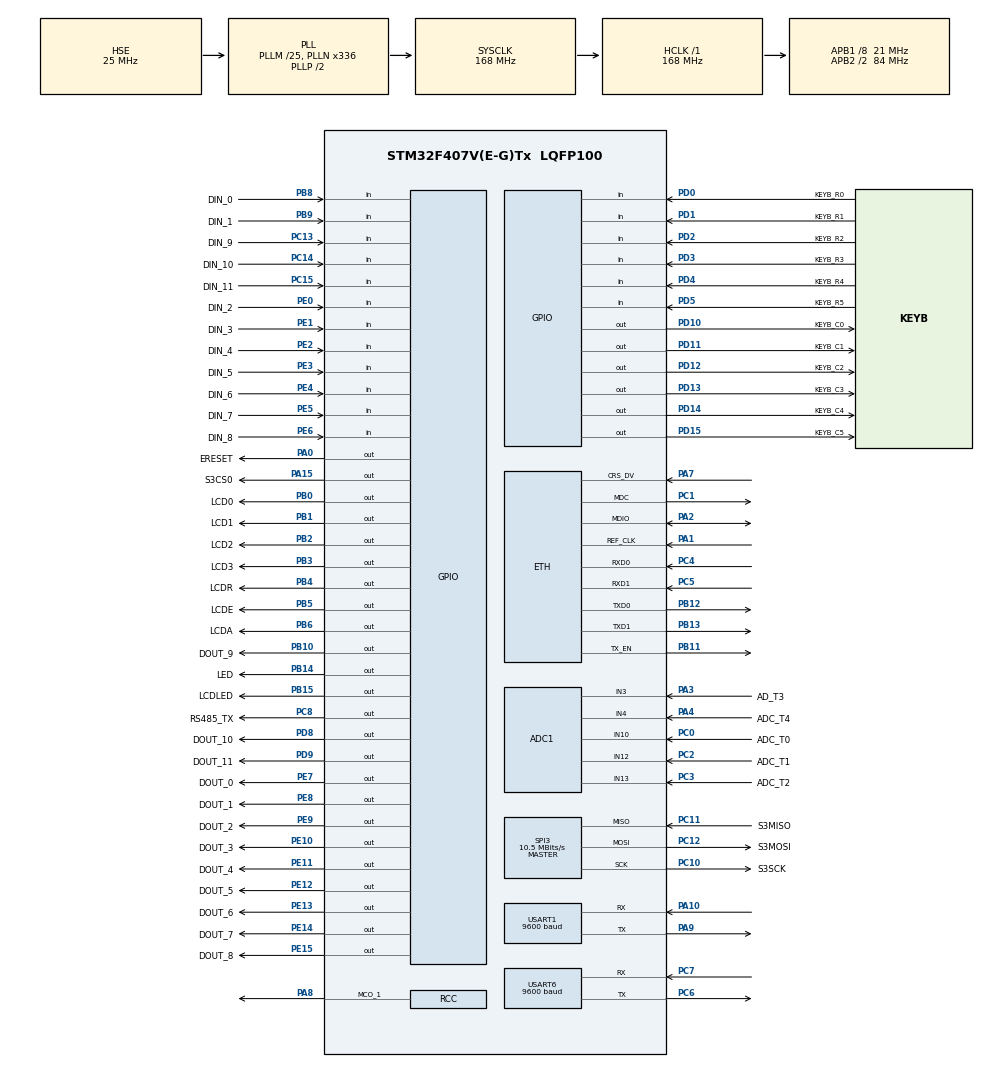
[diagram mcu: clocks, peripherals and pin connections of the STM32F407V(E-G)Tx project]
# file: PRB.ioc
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ADC1.Channel-0\#ChannelRegularConversion=ADC_CHANNEL_10
ADC1.Channel-1\#ChannelRegularConversion=ADC_CHANNEL_12
ADC1.Channel-2\#ChannelRegularConversion=ADC_CHANNEL_13
ADC1.Channel-3\#ChannelRegularConversion=ADC_CHANNEL_3
ADC1.Channel-4\#ChannelRegularConversion=ADC_CHANNEL_4
ADC1.Channel-5\#ChannelRegularConversion=ADC_CHANNEL_VREFINT
ADC1.ContinuousConvMode=DISABLE
ADC1.DMAContinuousRequests=ENABLE
ADC1.ExternalTrigConv=ADC_EXTERNALTRIGCONV_T3_TRGO
ADC1.InjNumberOfConversion=0
ADC1.NbrOfConversion=6
ADC1.NbrOfConversionFlag=1
ADC1.Rank-0\#ChannelRegularConversion=1
ADC1.Rank-1\#ChannelRegularConversion=2
ADC1.Rank-2\#ChannelRegularConversion=3
ADC1.Rank-3\#ChannelRegularConversion=4
ADC1.Rank-4\#ChannelRegularConversion=5
ADC1.Rank-5\#ChannelRegularConversion=6
ADC1.SamplingTime-0\#ChannelRegularConversion=ADC_SAMPLETIME_480CYCLES
ADC1.SamplingTime-1\#ChannelRegularConversion=ADC_SAMPLETIME_480CYCLES
ADC1.SamplingTime-2\#ChannelRegularConversion=ADC_SAMPLETIME_480CYCLES
ADC1.SamplingTime-3\#ChannelRegularConversion=ADC_SAMPLETIME_480CYCLES
ADC1.SamplingTime-4\#ChannelRegularConversion=ADC_SAMPLETIME_480CYCLES
ADC1.SamplingTime-5\#ChannelRegularConversion=ADC_SAMPLETIME_480CYCLES
ADC1.ScanConvMode=ENABLE
ADC1.master=1
Dma.ADC1.2.Direction=DMA_PERIPH_TO_MEMORY
Dma.ADC1.2.FIFOMode=DMA_FIFOMODE_DISABLE
Dma.ADC1.2.Instance=DMA2_Stream0
Dma.ADC1.2.MemDataAlignment=DMA_MDATAALIGN_HALFWORD
Dma.ADC1.2.MemInc=DMA_MINC_ENABLE
Dma.ADC1.2.Mode=DMA_CIRCULAR
Dma.ADC1.2.PeriphDataAlignment=DMA_PDATAALIGN_HALFWORD
Dma.ADC1.2.PeriphInc=DMA_PINC_DISABLE
Dma.ADC1.2.Priority=DMA_PRIORITY_LOW
Dma.Request0=USART1_RX
Dma.Request1=USART6_RX
Dma.Request2=ADC1
Dma.USART1_RX.0.Direction=DMA_PERIPH_TO_MEMORY
Dma.USART1_RX.0.FIFOMode=DMA_FIFOMODE_DISABLE
Dma.USART1_RX.0.Instance=DMA2_Stream2
Dma.USART1_RX.0.MemDataAlignment=DMA_MDATAALIGN_BYTE
Dma.USART1_RX.0.MemInc=DMA_MINC_ENABLE
Dma.USART1_RX.0.Mode=DMA_NORMAL
Dma.USART1_RX.0.PeriphDataAlignment=DMA_PDATAALIGN_BYTE
Dma.USART1_RX.0.PeriphInc=DMA_PINC_DISABLE
Dma.USART1_RX.0.Priority=DMA_PRIORITY_LOW
Dma.USART6_RX.1.Direction=DMA_PERIPH_TO_MEMORY
Dma.USART6_RX.1.FIFOMode=DMA_FIFOMODE_DISABLE
Dma.USART6_RX.1.Instance=DMA2_Stream1
Dma.USART6_RX.1.MemDataAlignment=DMA_MDATAALIGN_BYTE
Dma.USART6_RX.1.MemInc=DMA_MINC_ENABLE
Dma.USART6_RX.1.Mode=DMA_NORMAL
Dma.USART6_RX.1.PeriphDataAlignment=DMA_PDATAALIGN_BYTE
Dma.USART6_RX.1.PeriphInc=DMA_PINC_DISABLE
Dma.USART6_RX.1.Priority=DMA_PRIORITY_LOW
ETH.AutoNegotiation=ETH_AUTONEGOTIATION_ENABLE
ETH.DuplexMode=ETH_MODE_FULLDUPLEX
ETH.MACAddr=00\:80\:E1\:00\:13\:00
ETH.MediaInterface=ETH_MEDIA_INTERFACE_RMII
ETH.PhyAddress=0
FREERTOS.BinarySemaphores01=writeMemorySemaphore,Dynamic,NULL
FREERTOS.Tasks01=defaultTask,0,128,StartDefaultTask,Default,NULL,Dynamic,NULL,NULL
FREERTOS.configTOTAL_HEAP_SIZE=25360
FREERTOS.configUSE_NEWLIB_REENTRANT=1
LWIP.GATEWAY_ADDRESS=192.168.001.001
LWIP.IP_ADDRESS=192.168.001.177
LWIP.LWIP_DHCP=0
LWIP.NETMASK_ADDRESS=255.255.255.000
LWIP.Version=v2.1.2_Cube
Mcu.Family=STM32F4
Mcu.Name=STM32F407V(E-G)Tx
Mcu.Package=LQFP100
NVIC.DMA2_Stream0_IRQn=true\:5\:0\:false\:false\:true\:true\:false\:true
NVIC.DMA2_Stream1_IRQn=true\:5\:0\:false\:false\:true\:true\:false\:true
NVIC.DMA2_Stream2_IRQn=true\:5\:0\:false\:false\:true\:true\:false\:true
NVIC.ETH_IRQn=true\:5\:0\:false\:false\:true\:true\:false\:true
NVIC.PriorityGroup=NVIC_PRIORITYGROUP_4
NVIC.TIM1_UP_TIM10_IRQn=true\:15\:0\:false\:false\:true\:false\:false\:true
NVIC.TIM4_IRQn=true\:5\:0\:false\:false\:true\:true\:true\:true
NVIC.TimeBase=TIM1_UP_TIM10_IRQn
NVIC.TimeBaseIP=TIM1
NVIC.USART1_IRQn=true\:5\:0\:false\:false\:true\:true\:true\:true
NVIC.USART6_IRQn=true\:5\:0\:false\:false\:true\:true\:true\:true
PA0-WKUP.GPIO_Label=ERESET
PA0-WKUP.Signal=GPIO_Output
PA1.Mode=RMII
PA1.Signal=ETH_REF_CLK
PA10.GPIO_PuPd=GPIO_NOPULL
PA10.Mode=Asynchronous
PA10.Signal=USART1_RX
PA13.Mode=Serial_Wire
PA13.Signal=SYS_JTMS-SWDIO
PA14.Mode=Serial_Wire
PA14.Signal=SYS_JTCK-SWCLK
PA15.GPIO_Label=S3CS0
PA15.PinState=GPIO_PIN_SET
PA15.Signal=GPIO_Output
PA2.Mode=RMII
PA2.Signal=ETH_MDIO
PA3.GPIO_Label=AD_T3
PA3.Signal=ADCx_IN3
PA4.GPIO_Label=ADC_T4
PA4.Signal=ADCx_IN4
PA7.Mode=RMII
PA7.Signal=ETH_CRS_DV
PA8.Mode=Clock-out-1
PA8.Signal=RCC_MCO_1
PA9.Mode=Asynchronous
PA9.Signal=USART1_TX
PB0.GPIO_Label=LCD0
PB0.Signal=GPIO_Output
PB1.GPIO_Label=LCD1
PB1.Signal=GPIO_Output
PB10.GPIO_Label=DOUT_9
PB10.Signal=GPIO_Output
PB11.Mode=RMII
PB11.Signal=ETH_TX_EN
PB12.Mode=RMII
PB12.Signal=ETH_TXD0
PB13.Mode=RMII
PB13.Signal=ETH_TXD1
PB14.GPIO_Label=LED
PB14.Signal=GPIO_Output
PB15.GPIO_Label=LCDLED
PB15.Signal=GPIO_Output
PB2.GPIO_Label=LCD2
PB2.Signal=GPIO_Output
PB3.GPIO_Label=LCD3
PB3.Signal=GPIO_Output
PB4.GPIO_Label=LCDR
PB4.Signal=GPIO_Output
PB5.GPIO_Label=LCDE
PB5.Signal=GPIO_Output
PB6.GPIO_Label=LCDA
PB6.Signal=GPIO_Output
PB8.GPIO_Label=DIN_0
PB8.GPIO_PuPd=GPIO_PULLUP
PB8.Signal=GPIO_Input
PB9.GPIO_Label=DIN_1
PB9.GPIO_PuPd=GPIO_PULLUP
PB9.Signal=GPIO_Input
PC0.GPIO_Label=ADC_T0
PC0.Signal=ADCx_IN10
PC1.Mode=RMII
PC1.Signal=ETH_MDC
PC10.GPIO_Label=S3SCK
PC10.Mode=Full_Duplex_Master
PC10.Signal=SPI3_SCK
PC11.GPIO_Label=S3MISO
PC11.Mode=Full_Duplex_Master
PC11.Signal=SPI3_MISO
PC12.GPIO_Label=S3MOSI
PC12.Mode=Full_Duplex_Master
PC12.Signal=SPI3_MOSI
PC13-ANTI_TAMP.GPIO_Label=DIN_9
PC13-ANTI_TAMP.GPIO_PuPd=GPIO_PULLUP
PC13-ANTI_TAMP.Signal=GPIO_Input
PC14-OSC32_IN.GPIO_Label=DIN_10
PC14-OSC32_IN.GPIO_PuPd=GPIO_PULLUP
PC14-OSC32_IN.Signal=GPIO_Input
PC15-OSC32_OUT.GPIO_Label=DIN_11
PC15-OSC32_OUT.GPIO_PuPd=GPIO_PULLUP
PC15-OSC32_OUT.Signal=GPIO_Input
PC2.GPIO_Label=ADC_T1
PC2.Signal=ADCx_IN12
PC3.GPIO_Label=ADC_T2
PC3.Signal=ADCx_IN13
PC4.Mode=RMII
PC4.Signal=ETH_RXD0
PC5.Mode=RMII
PC5.Signal=ETH_RXD1
PC6.Mode=Asynchronous
PC6.Signal=USART6_TX
PC7.Mode=Asynchronous
PC7.Signal=USART6_RX
PC8.GPIO_Label=RS485_TX
PC8.Signal=GPIO_Output
PD0.GPIO_Label=KEYB_R0
PD0.GPIO_PuPd=GPIO_PULLDOWN
PD0.Signal=GPIO_Input
PD1.GPIO_Label=KEYB_R1
PD1.GPIO_PuPd=GPIO_PULLDOWN
PD1.Signal=GPIO_Input
PD10.GPIO_Label=KEYB_C0
PD10.Signal=GPIO_Output
PD11.GPIO_Label=KEYB_C1
PD11.Signal=GPIO_Output
PD12.GPIO_Label=KEYB_C2
PD12.Signal=GPIO_Output
PD13.GPIO_Label=KEYB_C3
PD13.Signal=GPIO_Output
PD14.GPIO_Label=KEYB_C4
PD14.Signal=GPIO_Output
PD15.GPIO_Label=KEYB_C5
PD15.Signal=GPIO_Output
PD2.GPIO_Label=KEYB_R2
PD2.GPIO_PuPd=GPIO_PULLDOWN
PD2.Signal=GPIO_Input
PD3.GPIO_Label=KEYB_R3
PD3.GPIO_PuPd=GPIO_PULLDOWN
PD3.Signal=GPIO_Input
PD4.GPIO_Label=KEYB_R4
PD4.GPIO_PuPd=GPIO_PULLDOWN
PD4.Signal=GPIO_Input
PD5.GPIO_Label=KEYB_R5
PD5.GPIO_PuPd=GPIO_PULLDOWN
PD5.Signal=GPIO_Input
PD8.GPIO_Label=DOUT_10
PD8.Signal=GPIO_Output
PD9.GPIO_Label=DOUT_11
PD9.Signal=GPIO_Output
PE0.GPIO_Label=DIN_2
PE0.GPIO_PuPd=GPIO_PULLUP
PE0.Signal=GPIO_Input
PE1.GPIO_Label=DIN_3
PE1.GPIO_PuPd=GPIO_PULLUP
PE1.Signal=GPIO_Input
PE10.GPIO_Label=DOUT_3
PE10.Signal=GPIO_Output
PE11.GPIO_Label=DOUT_4
PE11.Signal=GPIO_Output
PE12.GPIO_Label=DOUT_5
PE12.Signal=GPIO_Output
PE13.GPIO_Label=DOUT_6
PE13.Signal=GPIO_Output
PE14.GPIO_Label=DOUT_7
PE14.Signal=GPIO_Output
PE15.GPIO_Label=DOUT_8
PE15.Signal=GPIO_Output
PE2.GPIO_Label=DIN_4
PE2.GPIO_PuPd=GPIO_PULLUP
PE2.Signal=GPIO_Input
PE3.GPIO_Label=DIN_5
PE3.GPIO_PuPd=GPIO_PULLUP
PE3.Signal=GPIO_Input
PE4.GPIO_Label=DIN_6
PE4.GPIO_PuPd=GPIO_PULLUP
PE4.Signal=GPIO_Input
PE5.GPIO_Label=DIN_7
PE5.GPIO_PuPd=GPIO_PULLUP
PE5.Signal=GPIO_Input
PE6.GPIO_Label=DIN_8
PE6.GPIO_PuPd=GPIO_PULLUP
PE6.Signal=GPIO_Input
PE7.GPIO_Label=DOUT_0
PE7.PinState=GPIO_PIN_RESET
PE7.Signal=GPIO_Output
PE8.GPIO_Label=DOUT_1
PE8.Signal=GPIO_Output
PE9.GPIO_Label=DOUT_2
PE9.Signal=GPIO_Output
PH0-OSC_IN.Mode=HSE-External-Oscillator
PH0-OSC_IN.Signal=RCC_OSC_IN
PH1-OSC_OUT.Mode=HSE-External-Oscillator
PH1-OSC_OUT.Signal=RCC_OSC_OUT
ProjectManager.HeapSize=0x200
ProjectManager.StackSize=0x400
ProjectManager.TargetToolchain=STM32CubeIDE
RCC.48MHZClocksFreq_Value=84000000
RCC.AHBFreq_Value=168000000
RCC.APB1CLKDivider=RCC_HCLK_DIV8
RCC.APB1Freq_Value=21000000
RCC.APB1TimFreq_Value=42000000
RCC.APB2CLKDivider=RCC_HCLK_DIV2
RCC.APB2Freq_Value=84000000
RCC.APB2TimFreq_Value=168000000
RCC.CortexFreq_Value=168000000
RCC.HCLKFreq_Value=168000000
RCC.HSE_VALUE=25000000
RCC.HSI_VALUE=16000000
RCC.LSE_VALUE=32768
RCC.PLLM=25
RCC.PLLN=336
RCC.PLLSourceVirtual=RCC_PLLSOURCE_HSE
RCC.RCC_MCO1Source=RCC_MCO1SOURCE_HSE
RCC.SYSCLKFreq_VALUE=168000000
RCC.SYSCLKSource=RCC_SYSCLKSOURCE_PLLCLK
RCC.VCOOutputFreq_Value=336000000
SH.ADCx_IN10.0=ADC1_IN10,IN10
SH.ADCx_IN12.0=ADC1_IN12,IN12
SH.ADCx_IN13.0=ADC1_IN13,IN13
SH.ADCx_IN3.0=ADC1_IN3,IN3
SH.ADCx_IN4.0=ADC1_IN4,IN4
SPI3.BaudRatePrescaler=SPI_BAUDRATEPRESCALER_2
SPI3.CalculateBaudRate=10.5 MBits/s
SPI3.Direction=SPI_DIRECTION_2LINES
SPI3.Mode=SPI_MODE_MASTER
SPI3.VirtualType=VM_MASTER
TIM3.Period=9999
TIM3.Prescaler=41
TIM3.TIM_MasterOutputTrigger=TIM_TRGO_UPDATE
TIM4.Period=999
TIM4.Prescaler=41
TIM4.TIM_MasterOutputTrigger=TIM_TRGO_UPDATE
USART1.BaudRate=9600
USART1.Mode=MODE_TX_RX
USART1.VirtualMode=VM_ASYNC
USART1.WordLength=WORDLENGTH_8B
USART6.BaudRate=9600
USART6.VirtualMode=VM_ASYNC
USART6.WordLength=WORDLENGTH_8B
VP_ADC1_Vref_Input.Mode=IN-Vrefint
VP_FREERTOS_VS_CMSIS_V1.Mode=CMSIS_V1
VP_LWIP_VS_Enabled.Mode=Enabled
VP_SYS_VS_tim1.Mode=TIM1
VP_TIM3_VS_ClockSourceINT.Mode=Internal
VP_TIM4_VS_ClockSourceINT.Mode=Internal
board=custom

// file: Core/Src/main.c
/* USER CODE BEGIN Header */
/**
  ******************************************************************************
  * @file           : main.c
  * @brief          : Main program body
  ******************************************************************************
  * @attention
  *
  * Copyright (c) 2022 STMicroelectronics.
  * All rights reserved.
  *
  * This software is licensed under terms that can be found in the LICENSE file
  * in the root directory of this software component.
  * If no LICENSE file comes with this software, it is provided AS-IS.
  *
  ******************************************************************************
  */
/* USER CODE END Header */
#include "main.h"
#include "cmsis_os.h"
#include "lwip.h"

/* USER CODE BEGIN Includes */
#include <task_init.h>
#include <modbus.h>
#include <settings.h>
#include <main_process.h>
#include <lcd.h>
#include <uart_task.h>
#include <ethernet.h>
#include <analog.h>
#include <timer.h>

/* USER CODE END Includes */

ADC_HandleTypeDef hadc1;
DMA_HandleTypeDef hdma_adc1;

SPI_HandleTypeDef hspi3;

TIM_HandleTypeDef htim3;
TIM_HandleTypeDef htim4;

UART_HandleTypeDef huart1;
UART_HandleTypeDef huart6;
DMA_HandleTypeDef hdma_usart1_rx;
DMA_HandleTypeDef hdma_usart6_rx;

osThreadId defaultTaskHandle;
osSemaphoreId writeMemorySemaphoreHandle;

void SystemClock_Config(void);
static void MX_GPIO_Init(void);
static void MX_DMA_Init(void);
static void MX_USART1_UART_Init(void);
static void MX_USART6_UART_Init(void);
static void MX_SPI3_Init(void);
static void MX_ADC1_Init(void);
static void MX_TIM3_Init(void);
static void MX_TIM4_Init(void);
void StartDefaultTask(void const * argument);

int main(void)
{
  /* USER CODE BEGIN 1 */
	ModbusInit();
  /* USER CODE END 1 */

  /* MCU Configuration--------------------------------------------------------*/

  /* Reset of all peripherals, Initializes the Flash interface and the Systick. */
  HAL_Init();

  /* Configure the system clock */
  SystemClock_Config();

  /* Initialize all configured peripherals */
  MX_GPIO_Init();
  MX_DMA_Init();
  MX_USART1_UART_Init();
  MX_USART6_UART_Init();
  MX_SPI3_Init();
  MX_ADC1_Init();
  MX_TIM3_Init();
  MX_TIM4_Init();
  /* USER CODE BEGIN 2 */
  lcd_init();
  ethernet_reset();
  Analog_Start();
  Start_Timers();
  settingsLoadFRAM();

  /* USER CODE END 2 */

  /* Create the semaphores(s) */
  /* definition and creation of writeMemorySemaphore */
  osSemaphoreDef(writeMemorySemaphore);
  writeMemorySemaphoreHandle = osSemaphoreCreate(osSemaphore(writeMemorySemaphore), 1);

  /* Create the thread(s) */
  /* definition and creation of defaultTask */
  osThreadDef(defaultTask, StartDefaultTask, osPriorityNormal, 0, 128);
  defaultTaskHandle = osThreadCreate(osThread(defaultTask), NULL);

  /* Start scheduler */
  osKernelStart();

  /* We should never get here as control is now taken by the scheduler */
  /* Infinite loop */
  while (1)
  {

  }
}

void SystemClock_Config(void)
{
  RCC_OscInitTypeDef RCC_OscInitStruct = {0};
  RCC_ClkInitTypeDef RCC_ClkInitStruct = {0};

  /** Configure the main internal regulator output voltage
  */
  __HAL_RCC_PWR_CLK_ENABLE();
  __HAL_PWR_VOLTAGESCALING_CONFIG(PWR_REGULATOR_VOLTAGE_SCALE1);
  /** Initializes the RCC Oscillators according to the specified parameters
  * in the RCC_OscInitTypeDef structure.
  */
  RCC_OscInitStruct.OscillatorType = RCC_OSCILLATORTYPE_HSE;
  RCC_OscInitStruct.HSEState = RCC_HSE_ON;
  RCC_OscInitStruct.PLL.PLLState = RCC_PLL_ON;
  RCC_OscInitStruct.PLL.PLLSource = RCC_PLLSOURCE_HSE;
  RCC_OscInitStruct.PLL.PLLM = 25;
  RCC_OscInitStruct.PLL.PLLN = 336;
  RCC_OscInitStruct.PLL.PLLP = RCC_PLLP_DIV2;
  RCC_OscInitStruct.PLL.PLLQ = 4;
  if (HAL_RCC_OscConfig(&RCC_OscInitStruct) != HAL_OK)
  {
    Error_Handler();
  }
  /** Initializes the CPU, AHB and APB buses clocks
  */
  RCC_ClkInitStruct.ClockType = RCC_CLOCKTYPE_HCLK|RCC_CLOCKTYPE_SYSCLK
                              |RCC_CLOCKTYPE_PCLK1|RCC_CLOCKTYPE_PCLK2;
  RCC_ClkInitStruct.SYSCLKSource = RCC_SYSCLKSOURCE_PLLCLK;
  RCC_ClkInitStruct.AHBCLKDivider = RCC_SYSCLK_DIV1;
  RCC_ClkInitStruct.APB1CLKDivider = RCC_HCLK_DIV8;
  RCC_ClkInitStruct.APB2CLKDivider = RCC_HCLK_DIV2;

  if (HAL_RCC_ClockConfig(&RCC_ClkInitStruct, FLASH_LATENCY_5) != HAL_OK)
  {
    Error_Handler();
  }
  HAL_RCC_MCOConfig(RCC_MCO1, RCC_MCO1SOURCE_HSE, RCC_MCODIV_1);
}

static void MX_ADC1_Init(void)
{

  ADC_ChannelConfTypeDef sConfig = {0};

  /** Configure the global features of the ADC (Clock, Resolution, Data Alignment and number of conversion)
  */
  hadc1.Instance = ADC1;
  hadc1.Init.ClockPrescaler = ADC_CLOCK_SYNC_PCLK_DIV4;
  hadc1.Init.Resolution = ADC_RESOLUTION_12B;
  hadc1.Init.ScanConvMode = ENABLE;
  hadc1.Init.ContinuousConvMode = DISABLE;
  hadc1.Init.DiscontinuousConvMode = DISABLE;
  hadc1.Init.ExternalTrigConvEdge = ADC_EXTERNALTRIGCONVEDGE_RISING;
  hadc1.Init.ExternalTrigConv = ADC_EXTERNALTRIGCONV_T3_TRGO;
  hadc1.Init.DataAlign = ADC_DATAALIGN_RIGHT;
  hadc1.Init.NbrOfConversion = 6;
  hadc1.Init.DMAContinuousRequests = ENABLE;
  hadc1.Init.EOCSelection = ADC_EOC_SINGLE_CONV;
  if (HAL_ADC_Init(&hadc1) != HAL_OK)
  {
    Error_Handler();
  }
  /** Configure for the selected ADC regular channel its corresponding rank in the sequencer and its sample time.
  */
  sConfig.Channel = ADC_CHANNEL_10;
  sConfig.Rank = 1;
  sConfig.SamplingTime = ADC_SAMPLETIME_480CYCLES;
  if (HAL_ADC_ConfigChannel(&hadc1, &sConfig) != HAL_OK)
  {
    Error_Handler();
  }
  /** Configure for the selected ADC regular channel its corresponding rank in the sequencer and its sample time.
  */
  sConfig.Channel = ADC_CHANNEL_12;
  sConfig.Rank = 2;
  if (HAL_ADC_ConfigChannel(&hadc1, &sConfig) != HAL_OK)
  {
    Error_Handler();
  }
  /** Configure for the selected ADC regular channel its corresponding rank in the sequencer and its sample time.
  */
  sConfig.Channel = ADC_CHANNEL_13;
  sConfig.Rank = 3;
  if (HAL_ADC_ConfigChannel(&hadc1, &sConfig) != HAL_OK)
  {
    Error_Handler();
  }
  /** Configure for the selected ADC regular channel its corresponding rank in the sequencer and its sample time.
  */
  sConfig.Channel = ADC_CHANNEL_3;
  sConfig.Rank = 4;
  if (HAL_ADC_ConfigChannel(&hadc1, &sConfig) != HAL_OK)
  {
    Error_Handler();
  }
  /** Configure for the selected ADC regular channel its corresponding rank in the sequencer and its sample time.
  */
  sConfig.Channel = ADC_CHANNEL_4;
  sConfig.Rank = 5;
  if (HAL_ADC_ConfigChannel(&hadc1, &sConfig) != HAL_OK)
  {
    Error_Handler();
  }
  /** Configure for the selected ADC regular channel its corresponding rank in the sequencer and its sample time.
  */
  sConfig.Channel = ADC_CHANNEL_VREFINT;
  sConfig.Rank = 6;
  if (HAL_ADC_ConfigChannel(&hadc1, &sConfig) != HAL_OK)
  {
    Error_Handler();
  }

}

static void MX_SPI3_Init(void)
{

  /* SPI3 parameter configuration*/
  hspi3.Instance = SPI3;
  hspi3.Init.Mode = SPI_MODE_MASTER;
  hspi3.Init.Direction = SPI_DIRECTION_2LINES;
  hspi3.Init.DataSize = SPI_DATASIZE_8BIT;
  hspi3.Init.CLKPolarity = SPI_POLARITY_LOW;
  hspi3.Init.CLKPhase = SPI_PHASE_1EDGE;
  hspi3.Init.NSS = SPI_NSS_SOFT;
  hspi3.Init.BaudRatePrescaler = SPI_BAUDRATEPRESCALER_2;
  hspi3.Init.FirstBit = SPI_FIRSTBIT_MSB;
  hspi3.Init.TIMode = SPI_TIMODE_DISABLE;
  hspi3.Init.CRCCalculation = SPI_CRCCALCULATION_DISABLE;
  hspi3.Init.CRCPolynomial = 10;
  if (HAL_SPI_Init(&hspi3) != HAL_OK)
  {
    Error_Handler();
  }

}

static void MX_TIM3_Init(void)
{

  TIM_ClockConfigTypeDef sClockSourceConfig = {0};
  TIM_MasterConfigTypeDef sMasterConfig = {0};

  htim3.Instance = TIM3;
  htim3.Init.Prescaler = 41;
  htim3.Init.CounterMode = TIM_COUNTERMODE_UP;
  htim3.Init.Period = 9999;
  htim3.Init.ClockDivision = TIM_CLOCKDIVISION_DIV1;
  htim3.Init.AutoReloadPreload = TIM_AUTORELOAD_PRELOAD_DISABLE;
  if (HAL_TIM_Base_Init(&htim3) != HAL_OK)
  {
    Error_Handler();
  }
  sClockSourceConfig.ClockSource = TIM_CLOCKSOURCE_INTERNAL;
  if (HAL_TIM_ConfigClockSource(&htim3, &sClockSourceConfig) != HAL_OK)
  {
    Error_Handler();
  }
  sMasterConfig.MasterOutputTrigger = TIM_TRGO_UPDATE;
  sMasterConfig.MasterSlaveMode = TIM_MASTERSLAVEMODE_DISABLE;
  if (HAL_TIMEx_MasterConfigSynchronization(&htim3, &sMasterConfig) != HAL_OK)
  {
    Error_Handler();
  }

}

static void MX_TIM4_Init(void)
{

  TIM_ClockConfigTypeDef sClockSourceConfig = {0};
  TIM_MasterConfigTypeDef sMasterConfig = {0};

  htim4.Instance = TIM4;
  htim4.Init.Prescaler = 41;
  htim4.Init.CounterMode = TIM_COUNTERMODE_UP;
  htim4.Init.Period = 999;
  htim4.Init.ClockDivision = TIM_CLOCKDIVISION_DIV1;
  htim4.Init.AutoReloadPreload = TIM_AUTORELOAD_PRELOAD_DISABLE;
  if (HAL_TIM_Base_Init(&htim4) != HAL_OK)
  {
    Error_Handler();
  }
  sClockSourceConfig.ClockSource = TIM_CLOCKSOURCE_INTERNAL;
  if (HAL_TIM_ConfigClockSource(&htim4, &sClockSourceConfig) != HAL_OK)
  {
    Error_Handler();
  }
  sMasterConfig.MasterOutputTrigger = TIM_TRGO_UPDATE;
  sMasterConfig.MasterSlaveMode = TIM_MASTERSLAVEMODE_DISABLE;
  if (HAL_TIMEx_MasterConfigSynchronization(&htim4, &sMasterConfig) != HAL_OK)
  {
    Error_Handler();
  }

}

static void MX_USART1_UART_Init(void)
{

  huart1.Instance = USART1;
  huart1.Init.BaudRate = 9600;
  huart1.Init.WordLength = UART_WORDLENGTH_8B;
  huart1.Init.StopBits = UART_STOPBITS_1;
  huart1.Init.Parity = UART_PARITY_NONE;
  huart1.Init.Mode = UART_MODE_TX_RX;
  huart1.Init.HwFlowCtl = UART_HWCONTROL_NONE;
  huart1.Init.OverSampling = UART_OVERSAMPLING_16;
  if (HAL_UART_Init(&huart1) != HAL_OK)
  {
    Error_Handler();
  }

}

static void MX_USART6_UART_Init(void)
{

  huart6.Instance = USART6;
  huart6.Init.BaudRate = 9600;
  huart6.Init.WordLength = UART_WORDLENGTH_8B;
  huart6.Init.StopBits = UART_STOPBITS_1;
  huart6.Init.Parity = UART_PARITY_NONE;
  huart6.Init.Mode = UART_MODE_TX_RX;
  huart6.Init.HwFlowCtl = UART_HWCONTROL_NONE;
  huart6.Init.OverSampling = UART_OVERSAMPLING_16;
  if (HAL_UART_Init(&huart6) != HAL_OK)
  {
    Error_Handler();
  }

}

static void MX_DMA_Init(void)
{

  /* DMA controller clock enable */
  __HAL_RCC_DMA2_CLK_ENABLE();

  /* DMA interrupt init */
  /* DMA2_Stream0_IRQn interrupt configuration */
  HAL_NVIC_SetPriority(DMA2_Stream0_IRQn, 5, 0);
  HAL_NVIC_EnableIRQ(DMA2_Stream0_IRQn);
  /* DMA2_Stream1_IRQn interrupt configuration */
  HAL_NVIC_SetPriority(DMA2_Stream1_IRQn, 5, 0);
  HAL_NVIC_EnableIRQ(DMA2_Stream1_IRQn);
  /* DMA2_Stream2_IRQn interrupt configuration */
  HAL_NVIC_SetPriority(DMA2_Stream2_IRQn, 5, 0);
  HAL_NVIC_EnableIRQ(DMA2_Stream2_IRQn);

}

static void MX_GPIO_Init(void)
{
  GPIO_InitTypeDef GPIO_InitStruct = {0};

  /* GPIO Ports Clock Enable */
  __HAL_RCC_GPIOE_CLK_ENABLE();
  __HAL_RCC_GPIOC_CLK_ENABLE();
  __HAL_RCC_GPIOH_CLK_ENABLE();
  __HAL_RCC_GPIOA_CLK_ENABLE();
  __HAL_RCC_GPIOB_CLK_ENABLE();
  __HAL_RCC_GPIOD_CLK_ENABLE();

  /*Configure GPIO pin Output Level */
  HAL_GPIO_WritePin(ERESET_GPIO_Port, ERESET_Pin, GPIO_PIN_RESET);

  /*Configure GPIO pin Output Level */
  HAL_GPIO_WritePin(GPIOB, LCD0_Pin|LCD1_Pin|LCD2_Pin|DOUT_9_Pin
                          |LED_Pin|LCDLED_Pin|LCD3_Pin|LCDR_Pin
                          |LCDE_Pin|LCDA_Pin, GPIO_PIN_RESET);

  /*Configure GPIO pin Output Level */
  HAL_GPIO_WritePin(GPIOE, DOUT_0_Pin|DOUT_1_Pin|DOUT_2_Pin|DOUT_3_Pin
                          |DOUT_4_Pin|DOUT_5_Pin|DOUT_6_Pin|DOUT_7_Pin
                          |DOUT_8_Pin, GPIO_PIN_RESET);

  /*Configure GPIO pin Output Level */
  HAL_GPIO_WritePin(GPIOD, DOUT_10_Pin|DOUT_11_Pin|KEYB_C0_Pin|KEYB_C1_Pin
                          |KEYB_C2_Pin|KEYB_C3_Pin|KEYB_C4_Pin|KEYB_C5_Pin, GPIO_PIN_RESET);

  /*Configure GPIO pin Output Level */
  HAL_GPIO_WritePin(RS485_TX_GPIO_Port, RS485_TX_Pin, GPIO_PIN_RESET);

  /*Configure GPIO pin Output Level */
  HAL_GPIO_WritePin(S3CS0_GPIO_Port, S3CS0_Pin, GPIO_PIN_SET);

  /*Configure GPIO pins : DIN_4_Pin DIN_5_Pin DIN_6_Pin DIN_7_Pin
                           DIN_8_Pin DIN_2_Pin DIN_3_Pin */
  GPIO_InitStruct.Pin = DIN_4_Pin|DIN_5_Pin|DIN_6_Pin|DIN_7_Pin
                          |DIN_8_Pin|DIN_2_Pin|DIN_3_Pin;
  GPIO_InitStruct.Mode = GPIO_MODE_INPUT;
  GPIO_InitStruct.Pull = GPIO_PULLUP;
  HAL_GPIO_Init(GPIOE, &GPIO_InitStruct);

  /*Configure GPIO pins : DIN_9_Pin DIN_10_Pin DIN_11_Pin */
  GPIO_InitStruct.Pin = DIN_9_Pin|DIN_10_Pin|DIN_11_Pin;
  GPIO_InitStruct.Mode = GPIO_MODE_INPUT;
  GPIO_InitStruct.Pull = GPIO_PULLUP;
  HAL_GPIO_Init(GPIOC, &GPIO_InitStruct);

  /*Configure GPIO pins : ERESET_Pin S3CS0_Pin */
  GPIO_InitStruct.Pin = ERESET_Pin|S3CS0_Pin;
  GPIO_InitStruct.Mode = GPIO_MODE_OUTPUT_PP;
  GPIO_InitStruct.Pull = GPIO_NOPULL;
  GPIO_InitStruct.Speed = GPIO_SPEED_FREQ_LOW;
  HAL_GPIO_Init(GPIOA, &GPIO_InitStruct);

  /*Configure GPIO pins : LCD0_Pin LCD1_Pin LCD2_Pin DOUT_9_Pin
                           LED_Pin LCDLED_Pin LCD3_Pin LCDR_Pin
                           LCDE_Pin LCDA_Pin */
  GPIO_InitStruct.Pin = LCD0_Pin|LCD1_Pin|LCD2_Pin|DOUT_9_Pin
                          |LED_Pin|LCDLED_Pin|LCD3_Pin|LCDR_Pin
                          |LCDE_Pin|LCDA_Pin;
  GPIO_InitStruct.Mode = GPIO_MODE_OUTPUT_PP;
  GPIO_InitStruct.Pull = GPIO_NOPULL;
  GPIO_InitStruct.Speed = GPIO_SPEED_FREQ_LOW;
  HAL_GPIO_Init(GPIOB, &GPIO_InitStruct);

  /*Configure GPIO pins : DOUT_0_Pin DOUT_1_Pin DOUT_2_Pin DOUT_3_Pin
                           DOUT_4_Pin DOUT_5_Pin DOUT_6_Pin DOUT_7_Pin
                           DOUT_8_Pin */
  GPIO_InitStruct.Pin = DOUT_0_Pin|DOUT_1_Pin|DOUT_2_Pin|DOUT_3_Pin
                          |DOUT_4_Pin|DOUT_5_Pin|DOUT_6_Pin|DOUT_7_Pin
                          |DOUT_8_Pin;
  GPIO_InitStruct.Mode = GPIO_MODE_OUTPUT_PP;
  GPIO_InitStruct.Pull = GPIO_NOPULL;
  GPIO_InitStruct.Speed = GPIO_SPEED_FREQ_LOW;
  HAL_GPIO_Init(GPIOE, &GPIO_InitStruct);

  /*Configure GPIO pins : DOUT_10_Pin DOUT_11_Pin KEYB_C0_Pin KEYB_C1_Pin
                           KEYB_C2_Pin KEYB_C3_Pin KEYB_C4_Pin KEYB_C5_Pin */
  GPIO_InitStruct.Pin = DOUT_10_Pin|DOUT_11_Pin|KEYB_C0_Pin|KEYB_C1_Pin
                          |KEYB_C2_Pin|KEYB_C3_Pin|KEYB_C4_Pin|KEYB_C5_Pin;
  GPIO_InitStruct.Mode = GPIO_MODE_OUTPUT_PP;
  GPIO_InitStruct.Pull = GPIO_NOPULL;
  GPIO_InitStruct.Speed = GPIO_SPEED_FREQ_LOW;
  HAL_GPIO_Init(GPIOD, &GPIO_InitStruct);

  /*Configure GPIO pin : RS485_TX_Pin */
  GPIO_InitStruct.Pin = RS485_TX_Pin;
  GPIO_InitStruct.Mode = GPIO_MODE_OUTPUT_PP;
  GPIO_InitStruct.Pull = GPIO_NOPULL;
  GPIO_InitStruct.Speed = GPIO_SPEED_FREQ_LOW;
  HAL_GPIO_Init(RS485_TX_GPIO_Port, &GPIO_InitStruct);

  /*Configure GPIO pin : PA8 */
  GPIO_InitStruct.Pin = GPIO_PIN_8;
  GPIO_InitStruct.Mode = GPIO_MODE_AF_PP;
  GPIO_InitStruct.Pull = GPIO_NOPULL;
  GPIO_InitStruct.Speed = GPIO_SPEED_FREQ_LOW;
  GPIO_InitStruct.Alternate = GPIO_AF0_MCO;
  HAL_GPIO_Init(GPIOA, &GPIO_InitStruct);

  /*Configure GPIO pins : KEYB_R0_Pin KEYB_R1_Pin KEYB_R2_Pin KEYB_R3_Pin
                           KEYB_R4_Pin KEYB_R5_Pin */
  GPIO_InitStruct.Pin = KEYB_R0_Pin|KEYB_R1_Pin|KEYB_R2_Pin|KEYB_R3_Pin
                          |KEYB_R4_Pin|KEYB_R5_Pin;
  GPIO_InitStruct.Mode = GPIO_MODE_INPUT;
  GPIO_InitStruct.Pull = GPIO_PULLDOWN;
  HAL_GPIO_Init(GPIOD, &GPIO_InitStruct);

  /*Configure GPIO pins : DIN_0_Pin DIN_1_Pin */
  GPIO_InitStruct.Pin = DIN_0_Pin|DIN_1_Pin;
  GPIO_InitStruct.Mode = GPIO_MODE_INPUT;
  GPIO_InitStruct.Pull = GPIO_PULLUP;
  HAL_GPIO_Init(GPIOB, &GPIO_InitStruct);

}

void StartDefaultTask(void const * argument)
{
  /* init code for LWIP */
  MX_LWIP_Init();
  /* USER CODE BEGIN 5 */
  task_init();
  settingsLoadFRAM();
  main_process_init();
  /* Infinite loop */
  for(;;)
  {
	main_process();
    osDelay(1);
  }
  /* USER CODE END 5 */
}

void HAL_TIM_PeriodElapsedCallback(TIM_HandleTypeDef *htim)
{
  if (htim->Instance == TIM1) {
    HAL_IncTick();
  }
}

void Error_Handler(void)
{
  __disable_irq();
  while (1)
  {
  }
}

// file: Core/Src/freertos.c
/* USER CODE BEGIN Header */
/**
  ******************************************************************************
  * File Name          : freertos.c
  * Description        : Code for freertos applications
  ******************************************************************************
  * @attention
  *
  * Copyright (c) 2022 STMicroelectronics.
  * All rights reserved.
  *
  * This software is licensed under terms that can be found in the LICENSE file
  * in the root directory of this software component.
  * If no LICENSE file comes with this software, it is provided AS-IS.
  *
  ******************************************************************************
  */
/* USER CODE END Header */

#include "FreeRTOS.h"
#include "task.h"
#include "main.h"

/* USER CODE BEGIN Includes */
#include <task_init.h>
#include <ethernet.h>
#include <uart_task.h>
#include <cmsis_os.h>
#include <lwip.h>
#include <keyboard.h>

/* USER CODE END Includes */

/* USER CODE BEGIN Variables */
unsigned short port1=502;
unsigned short port2=503;
osMailQId uart_queue; // Id очереди для uart_task
/* USER CODE END Variables */

/* GetIdleTaskMemory prototype (linked to static allocation support) */
void vApplicationGetIdleTaskMemory( StaticTask_t **ppxIdleTaskTCBBuffer, StackType_t **ppxIdleTaskStackBuffer, uint32_t *pulIdleTaskStackSize );

/* USER CODE BEGIN GET_IDLE_TASK_MEMORY */
static StaticTask_t xIdleTaskTCBBuffer;
static StackType_t xIdleStack[configMINIMAL_STACK_SIZE];

void vApplicationGetIdleTaskMemory( StaticTask_t **ppxIdleTaskTCBBuffer, StackType_t **ppxIdleTaskStackBuffer, uint32_t *pulIdleTaskStackSize )
{
  *ppxIdleTaskTCBBuffer = &xIdleTaskTCBBuffer;
  *ppxIdleTaskStackBuffer = &xIdleStack[0];
  *pulIdleTaskStackSize = configMINIMAL_STACK_SIZE;
  /* place for user code */
}
/* USER CODE END GET_IDLE_TASK_MEMORY */

/* USER CODE BEGIN Application */
void task_init()
{
	size_t fre = 0;
	fre=xPortGetFreeHeapSize();
	sys_thread_new("eth_thread1", ethernet_thread, (void*)&port1, DEFAULT_THREAD_STACKSIZE, osPriorityNormal );
	fre=xPortGetFreeHeapSize();
	sys_thread_new("eth_thread2", ethernet_thread, (void*)&port2, DEFAULT_THREAD_STACKSIZE, osPriorityNormal );
	fre=xPortGetFreeHeapSize();
	sys_thread_new("uart_thread", uart_thread, (void*)NULL, 512, osPriorityNormal );
	fre=xPortGetFreeHeapSize();
	osMailQDef(uart_queue, 10, Uart_Queue_Struct);
	uart_queue = osMailCreate(osMailQ(uart_queue), NULL);
	sys_thread_new("keyboard_thread", keyscan_thread, (void*)NULL, 128, osPriorityNormal );
	fre=xPortGetFreeHeapSize();
}

/* USER CODE END Application */
